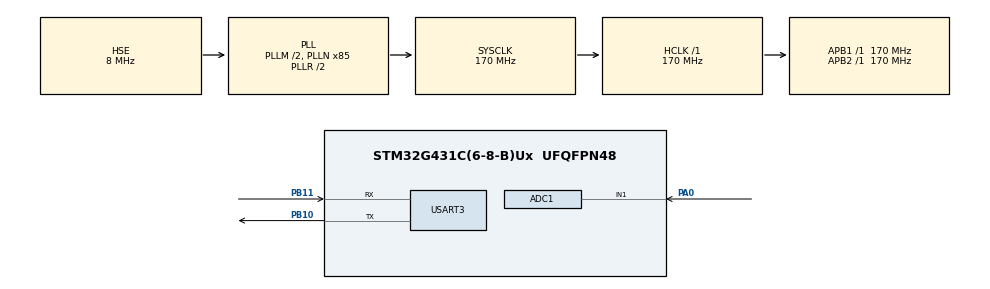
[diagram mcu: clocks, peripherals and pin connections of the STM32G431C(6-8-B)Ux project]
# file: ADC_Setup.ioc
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ADC1.ClockPrescaler=ADC_CLOCK_ASYNC_DIV4
ADC1.ContinuousConvMode=ENABLE
ADC1.NbrOfConversionFlag=1
ADC1.SamplingTime-0\#ChannelRegularConversion=ADC_SAMPLETIME_47CYCLES_5
ADC1.master=1
Dma.ADC1.0.Direction=DMA_PERIPH_TO_MEMORY
Dma.ADC1.0.EventEnable=DISABLE
Dma.ADC1.0.Instance=DMA1_Channel1
Dma.ADC1.0.MemDataAlignment=DMA_MDATAALIGN_HALFWORD
Dma.ADC1.0.MemInc=DMA_MINC_ENABLE
Dma.ADC1.0.Mode=DMA_NORMAL
Dma.ADC1.0.PeriphDataAlignment=DMA_PDATAALIGN_HALFWORD
Dma.ADC1.0.PeriphInc=DMA_PINC_DISABLE
Dma.ADC1.0.Polarity=HAL_DMAMUX_REQ_GEN_RISING
Dma.ADC1.0.Priority=DMA_PRIORITY_LOW
Dma.ADC1.0.RequestNumber=1
Dma.ADC1.0.SignalID=NONE
Dma.ADC1.0.SyncEnable=DISABLE
Dma.ADC1.0.SyncPolarity=HAL_DMAMUX_SYNC_NO_EVENT
Dma.ADC1.0.SyncRequestNumber=1
Dma.ADC1.0.SyncSignalID=NONE
Dma.Request0=ADC1
Mcu.Family=STM32G4
Mcu.Name=STM32G431C(6-8-B)Ux
Mcu.Package=UFQFPN48
NVIC.ADC1_2_IRQn=true\:0\:0\:false\:false\:true\:true\:true\:true
NVIC.DMA1_Channel1_IRQn=true\:0\:0\:false\:false\:true\:false\:true\:true
NVIC.PriorityGroup=NVIC_PRIORITYGROUP_4
PA0.Mode=IN1-Single-Ended
PA0.Signal=ADC1_IN1
PA13.Mode=Serial_Wire
PA13.Signal=SYS_JTMS-SWDIO
PA14.Mode=Serial_Wire
PA14.Signal=SYS_JTCK-SWCLK
PB10.Mode=Asynchronous
PB10.Signal=USART3_TX
PB11.Mode=Asynchronous
PB11.Signal=USART3_RX
PC14-OSC32_IN.Mode=LSE-External-Oscillator
PC14-OSC32_IN.Signal=RCC_OSC32_IN
PC15-OSC32_OUT.Mode=LSE-External-Oscillator
PC15-OSC32_OUT.Signal=RCC_OSC32_OUT
PF0-OSC_IN.Mode=HSE-External-Oscillator
PF0-OSC_IN.Signal=RCC_OSC_IN
PF1-OSC_OUT.Mode=HSE-External-Oscillator
PF1-OSC_OUT.Signal=RCC_OSC_OUT
ProjectManager.HeapSize=0x200
ProjectManager.StackSize=0x400
ProjectManager.TargetToolchain=MDK-ARM V5.32
RCC.ADC12Freq_Value=170000000
RCC.AHBFreq_Value=170000000
RCC.APB1Freq_Value=170000000
RCC.APB1TimFreq_Value=170000000
RCC.APB2Freq_Value=170000000
RCC.APB2TimFreq_Value=170000000
RCC.CortexFreq_Value=170000000
RCC.EXTERNAL_CLOCK_VALUE=12288000
RCC.HCLKFreq_Value=170000000
RCC.HSE_VALUE=8000000
RCC.HSI48_VALUE=48000000
RCC.HSI_VALUE=16000000
RCC.PLLM=RCC_PLLM_DIV2
RCC.PLLN=85
RCC.PLLSourceVirtual=RCC_PLLSOURCE_HSE
RCC.SYSCLKFreq_VALUE=170000000
RCC.SYSCLKSource=RCC_SYSCLKSOURCE_PLLCLK
RCC.USBFreq_Value=170000000
RCC.VCOOutputFreq_Value=340000000
USART3.VirtualMode-Asynchronous=VM_ASYNC
VP_SYS_VS_DBSignals.Mode=DisableDeadBatterySignals
board=custom

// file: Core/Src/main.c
/* USER CODE BEGIN Header */
/**
  ******************************************************************************
  * @file           : main.c
  * @brief          : Main program body
  ******************************************************************************
  * @attention
  *
  * Copyright (c) 2025 STMicroelectronics.
  * All rights reserved.
  *
  * This software is licensed under terms that can be found in the LICENSE file
  * in the root directory of this software component.
  * If no LICENSE file comes with this software, it is provided AS-IS.
  *
  ******************************************************************************
  */
/* USER CODE END Header */
#include "main.h"
#include "adc.h"
#include "dma.h"
#include "usart.h"
#include "gpio.h"

/* USER CODE BEGIN Includes */
#include <string.h>
#include <stdarg.h>
#include <stdio.h>
/* USER CODE END Includes */

/* USER CODE BEGIN PV */
uint16_t My_adcData [512]={0};
/* USER CODE END PV */

void SystemClock_Config(void);

/* USER CODE BEGIN 0 */
int myprintf(const char *format, ...)
{
    char buffer[128];
    va_list args;
    va_start(args, format);
    vsnprintf(buffer, sizeof(buffer), format, args);
    va_end(args);

    return HAL_UART_Transmit(&huart3, (uint8_t*)buffer, strlen(buffer), HAL_MAX_DELAY);
}
/* USER CODE END 0 */

int main(void)
{

  /* MCU Configuration--------------------------------------------------------*/

  /* Reset of all peripherals, Initializes the Flash interface and the Systick. */
  HAL_Init();

  /* Configure the system clock */
  SystemClock_Config();

  /* Initialize all configured peripherals */
  MX_GPIO_Init();
  MX_DMA_Init();
  MX_ADC1_Init();
  MX_USART3_UART_Init();
  /* USER CODE BEGIN 2 */
  myprintf("System Start!\n");
  HAL_ADC_Start_DMA(&hadc1, (uint32_t *)My_adcData, 512); // 用的哪个ADC，存在哪个数组里面，数组长度（采样点数）
  /* USER CODE END 2 */

  /* Infinite loop */
  while (1)
  {

  }
}

void SystemClock_Config(void)
{
  RCC_OscInitTypeDef RCC_OscInitStruct = {0};
  RCC_ClkInitTypeDef RCC_ClkInitStruct = {0};

  /** Configure the main internal regulator output voltage
  */
  HAL_PWREx_ControlVoltageScaling(PWR_REGULATOR_VOLTAGE_SCALE1_BOOST);

  /** Initializes the RCC Oscillators according to the specified parameters
  * in the RCC_OscInitTypeDef structure.
  */
  RCC_OscInitStruct.OscillatorType = RCC_OSCILLATORTYPE_HSE;
  RCC_OscInitStruct.HSEState = RCC_HSE_ON;
  RCC_OscInitStruct.PLL.PLLState = RCC_PLL_ON;
  RCC_OscInitStruct.PLL.PLLSource = RCC_PLLSOURCE_HSE;
  RCC_OscInitStruct.PLL.PLLM = RCC_PLLM_DIV2;
  RCC_OscInitStruct.PLL.PLLN = 85;
  RCC_OscInitStruct.PLL.PLLP = RCC_PLLP_DIV2;
  RCC_OscInitStruct.PLL.PLLQ = RCC_PLLQ_DIV2;
  RCC_OscInitStruct.PLL.PLLR = RCC_PLLR_DIV2;
  if (HAL_RCC_OscConfig(&RCC_OscInitStruct) != HAL_OK)
  {
    Error_Handler();
  }

  /** Initializes the CPU, AHB and APB buses clocks
  */
  RCC_ClkInitStruct.ClockType = RCC_CLOCKTYPE_HCLK|RCC_CLOCKTYPE_SYSCLK
                              |RCC_CLOCKTYPE_PCLK1|RCC_CLOCKTYPE_PCLK2;
  RCC_ClkInitStruct.SYSCLKSource = RCC_SYSCLKSOURCE_PLLCLK;
  RCC_ClkInitStruct.AHBCLKDivider = RCC_SYSCLK_DIV1;
  RCC_ClkInitStruct.APB1CLKDivider = RCC_HCLK_DIV1;
  RCC_ClkInitStruct.APB2CLKDivider = RCC_HCLK_DIV1;

  if (HAL_RCC_ClockConfig(&RCC_ClkInitStruct, FLASH_LATENCY_4) != HAL_OK)
  {
    Error_Handler();
  }
}

/* USER CODE BEGIN 4 */
void HAL_ADC_ConvCpltCallback(ADC_HandleTypeDef* hadc)
{
    if(hadc->Instance == ADC1)
    {
        for(int i = 0; i < 512; i++)
		{
			myprintf("ADC_Data[%d]:%d\n",i, My_adcData[i]);
		}
	}
}
/* USER CODE END 4 */

void Error_Handler(void)
{
  __disable_irq();
  while (1)
  {
  }
}
